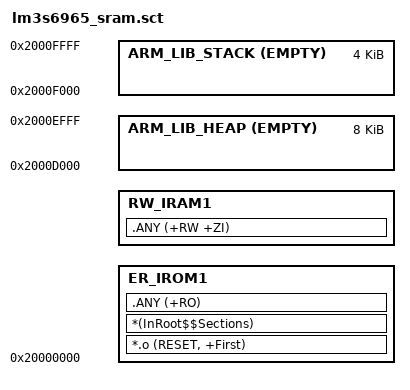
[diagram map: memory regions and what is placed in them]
;******************************************************************
;* LM3S6965 linker scatter file (running code from internal SRAM) *
;******************************************************************

LR_IROM1 0x20000000 0x10000
{
   ER_IROM1 0x20000000
   {
      *.o (RESET, +First)
      *(InRoot$$Sections)
      .ANY (+RO)
   }
   
   RW_IRAM1 +0
   { 
      .ANY (+RW +ZI)
   }
   
   ScatterAssert((ImageLength(ER_IROM1) + ImageLength(RW_IRAM1)) < 0xD000)
   
   ARM_LIB_STACK 0x20010000 EMPTY -0x1000
   {
   }
   
   ARM_LIB_HEAP 0x2000D000 EMPTY 0x2000
   {
   }
}
